AUTOSAR XML (schema 4-3-1)
package /Components
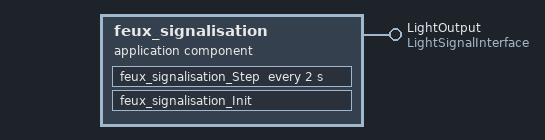
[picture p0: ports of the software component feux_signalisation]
  application sw component type feux_signalisation
    provide port LightOutput: nonqueued-sender-com-spec{data-element=couleur, init-value=0}, provided-interface=LightSignalInterface
    behavior feux_signalisation_IB: handle-termination-and-restart=NO-SUPPORT
      timing event Event_feux_signalisation_Step: start-on-event=feux_signalisation_Step, period=2
      runnable feux_signalisation_Init
      runnable feux_signalisation_Step
        data-write-access:
          access OUT_LightOutput_couleur: accessed-variable=LightOutput.couleur
